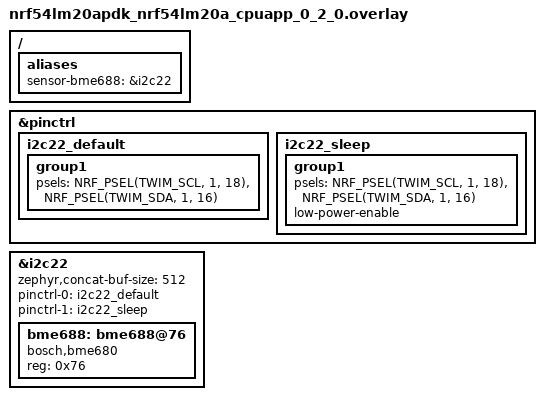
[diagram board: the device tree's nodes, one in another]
/ {
	aliases {
		sensor-bme688 = &i2c22;
	};
};

&pinctrl {
	i2c22_default: i2c22_default {
		group1  {
			psels = <NRF_PSEL(TWIM_SCL, 1, 18)>,
					<NRF_PSEL(TWIM_SDA, 1, 16)>;
		};
	};

	i2c22_sleep: i2c22_sleep {
		group1  {
			psels = <NRF_PSEL(TWIM_SCL, 1, 18)>,
					<NRF_PSEL(TWIM_SDA, 1, 16)>;
			low-power-enable;
		};
	};
};

&i2c22 {
	status = "okay";
	zephyr,concat-buf-size = <512>;
	pinctrl-0 = <&i2c22_default>;
	pinctrl-1 = <&i2c22_sleep>;
	pinctrl-names = "default", "sleep";

	bme688: bme688@76 {
		compatible = "bosch,bme680";
		status = "okay";
		reg = <0x76>;
	};
};
